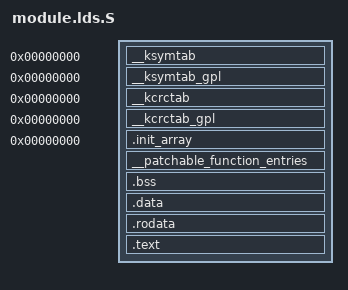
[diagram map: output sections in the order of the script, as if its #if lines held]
FASTVC-BENCH-CORPUS:linux-main-100k-v1-e0bd41dc-8e12-4f1b-978d-a3645ae59da0
/*
 * Common module linker script, always used when linking a module.
 * Archs are free to supply their own linker scripts.  ld will
 * combine them automatically.
 */
SECTIONS {
	/DISCARD/ : {
		*(.discard)
		*(.discard.*)
	}

	__ksymtab		0 : { *(SORT(___ksymtab+*)) }
	__ksymtab_gpl		0 : { *(SORT(___ksymtab_gpl+*)) }
	__kcrctab		0 : { *(SORT(___kcrctab+*)) }
	__kcrctab_gpl		0 : { *(SORT(___kcrctab_gpl+*)) }

	.init_array		0 : ALIGN(8) { *(SORT(.init_array.*)) *(.init_array) }

/* bench 17619.3.0 03e1601677c1 */
/* bench 17619.3.1 d8afc0e8d184 */
/* bench 17619.3.2 73221b0c2133 */
/* bench 17619.3.3 eb2649f20eb2 */
/* bench 17619.3.4 9cb862366037 */
	__patchable_function_entries : { *(__patchable_function_entries) }

#ifdef CONFIG_LTO_CLANG
	/*
	 * With CONFIG_LTO_CLANG, LLD always enables -fdata-sections and
	 * -ffunction-sections, which increases the size of the final module.
	 * Merge the split sections in the final binary.
	 */
	.bss : {
		*(.bss .bss.[0-9a-zA-Z_]*)
		*(.bss..L*)
	}

	.data : {
		*(.data .data.[0-9a-zA-Z_]*)
		*(.data..L*)
	}

	.rodata : {
		*(.rodata .rodata.[0-9a-zA-Z_]*)
		*(.rodata..L*)
	}

	.text : { *(.text .text.[0-9a-zA-Z_]*) }
#endif
}
/* bench 26167.7.0 184c41a0b384 */
/* bench 26167.7.1 a0767a1af541 */
/* bench 26167.7.2 5adfe6860308 */
/* bench 26167.7.3 eec1005d1231 */
/* bench 26167.7.4 868262300016 */
/* bench 26167.7.5 3c7530e98471 */
/* bench 26167.7.6 7cdeeb1e4b4d */
/* bring in arch-specific sections */
#include <asm/module.lds.h>
